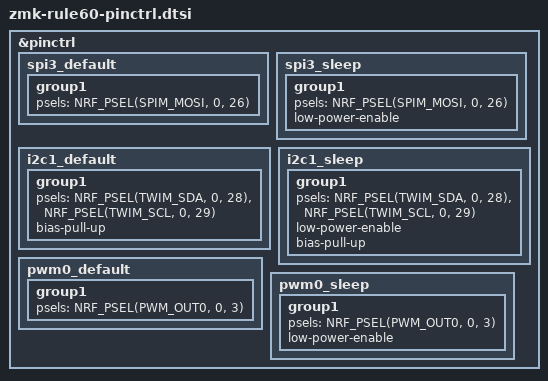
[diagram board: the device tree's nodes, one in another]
/*
 * Copyright (c) 2022 The ZMK Contributors
 * SPDX-License-Identifier: MIT
 */

&pinctrl {
    spi3_default: spi3_default {
        group1 {
            psels = <NRF_PSEL(SPIM_MOSI, 0, 26)>;
        };
    };

    spi3_sleep: spi3_sleep {
        group1 {
            psels = <NRF_PSEL(SPIM_MOSI, 0, 26)>;
            low-power-enable;
        };
    };

    i2c1_default: i2c1_default {
      group1 {
          psels = <NRF_PSEL(TWIM_SDA, 0, 28)>,
                  <NRF_PSEL(TWIM_SCL, 0, 29)>;
          bias-pull-up;
      };
    };

    i2c1_sleep: i2c1_sleep {
      group1 {
          psels = <NRF_PSEL(TWIM_SDA, 0, 28)>,
                  <NRF_PSEL(TWIM_SCL, 0, 29)>;
          low-power-enable;
          bias-pull-up;
      };
    };    

    // ryong60: 백라이트 PWM (P0.03)
    pwm0_default: pwm0_default {
        group1 {
            psels = <NRF_PSEL(PWM_OUT0, 0, 3)>;
        };
    };

    pwm0_sleep: pwm0_sleep {
        group1 {
            psels = <NRF_PSEL(PWM_OUT0, 0, 3)>;
            low-power-enable;
        };
    };
};
